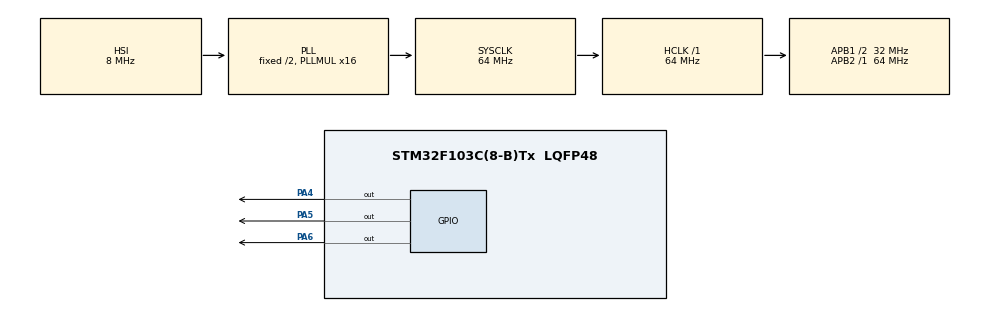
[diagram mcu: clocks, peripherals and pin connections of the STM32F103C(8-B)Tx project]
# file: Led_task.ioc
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Mcu.Family=STM32F1
Mcu.Name=STM32F103C(8-B)Tx
Mcu.Package=LQFP48
NVIC.PriorityGroup=NVIC_PRIORITYGROUP_4
NVIC.TIM4_IRQn=true\:15\:0\:false\:false\:true\:false\:true\:true
NVIC.TimeBase=TIM4_IRQn
NVIC.TimeBaseIP=TIM4
PA13.Mode=Serial_Wire
PA13.Signal=SYS_JTMS-SWDIO
PA14.Mode=Serial_Wire
PA14.Signal=SYS_JTCK-SWCLK
PA4.Signal=GPIO_Output
PA5.Signal=GPIO_Output
PA6.Signal=GPIO_Output
ProjectManager.HeapSize=0x200
ProjectManager.StackSize=0x400
ProjectManager.TargetToolchain=STM32CubeIDE
RCC.AHBFreq_Value=64000000
RCC.APB1CLKDivider=RCC_HCLK_DIV2
RCC.APB1Freq_Value=32000000
RCC.APB1TimFreq_Value=64000000
RCC.APB2Freq_Value=64000000
RCC.APB2TimFreq_Value=64000000
RCC.HCLKFreq_Value=64000000
RCC.PLLMUL=RCC_PLL_MUL16
RCC.SYSCLKFreq_VALUE=64000000
RCC.SYSCLKSource=RCC_SYSCLKSOURCE_PLLCLK
RCC.USBFreq_Value=64000000
VP_SYS_VS_tim4.Mode=TIM4
board=custom

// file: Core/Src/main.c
/* USER CODE BEGIN Header */
/**
  ******************************************************************************
  * @file           : main.c
  * @brief          : Main program body
  ******************************************************************************
  * @attention
  *
  * Copyright (c) 2023 STMicroelectronics.
  * All rights reserved.
  *
  * This software is licensed under terms that can be found in the LICENSE file
  * in the root directory of this software component.
  * If no LICENSE file comes with this software, it is provided AS-IS.
  *
  ******************************************************************************
  */
/* USER CODE END Header */
#include "main.h"

/* USER CODE BEGIN Includes */
#include "FreeRTOS.h"
#include "task.h"
/* USER CODE END Includes */

/* USER CODE BEGIN PV */
#define DWT_CTRL    (*(volatile uint32_t*)0xE0001000)
/* USER CODE END PV */

void SystemClock_Config(void);
static void MX_GPIO_Init(void);
/* USER CODE BEGIN PFP */
static void led_green_handler(void* parameters);
static void led_orange_handler(void* parameters);
static void led_red_handler(void* parameters);

/* USER CODE END PFP */

int main(void)
{
  /* USER CODE BEGIN 1 */
	TaskHandle_t task1_handle;
	TaskHandle_t task2_handle;
	TaskHandle_t task3_handle;
	BaseType_t status;
  /* USER CODE END 1 */

  /* MCU Configuration--------------------------------------------------------*/

  /* Reset of all peripherals, Initializes the Flash interface and the Systick. */
  HAL_Init();

  /* Configure the system clock */
  SystemClock_Config();

  /* Initialize all configured peripherals */
  MX_GPIO_Init();
  /* USER CODE BEGIN 2 */

  //CYCLCNT enable
  DWT_CTRL |= ( 1 << 0);

  SEGGER_SYSVIEW_Conf();
  SEGGER_SYSVIEW_Start();

  status = xTaskCreate(led_green_handler, "LED_green_task", 200, NULL, 2, &task1_handle);

  configASSERT(status == pdPASS);

  status = xTaskCreate(led_red_handler, "LED_red_task", 200,NULL, 2, &task2_handle);

  configASSERT(status == pdPASS);

  status = xTaskCreate(led_orange_handler, "LED_orange_task", 200, NULL, 2, &task3_handle);

  configASSERT(status == pdPASS);

  //start the freeRTOS scheduler
  vTaskStartScheduler();

  /* USER CODE END 2 */

  /* Infinite loop */
  while (1)
  {

  }
}

void SystemClock_Config(void)
{
  RCC_OscInitTypeDef RCC_OscInitStruct = {0};
  RCC_ClkInitTypeDef RCC_ClkInitStruct = {0};

  /** Initializes the RCC Oscillators according to the specified parameters
  * in the RCC_OscInitTypeDef structure.
  */
  RCC_OscInitStruct.OscillatorType = RCC_OSCILLATORTYPE_HSI;
  RCC_OscInitStruct.HSIState = RCC_HSI_ON;
  RCC_OscInitStruct.HSICalibrationValue = RCC_HSICALIBRATION_DEFAULT;
  RCC_OscInitStruct.PLL.PLLState = RCC_PLL_ON;
  RCC_OscInitStruct.PLL.PLLSource = RCC_PLLSOURCE_HSI_DIV2;
  RCC_OscInitStruct.PLL.PLLMUL = RCC_PLL_MUL16;
  if (HAL_RCC_OscConfig(&RCC_OscInitStruct) != HAL_OK)
  {
    Error_Handler();
  }

  /** Initializes the CPU, AHB and APB buses clocks
  */
  RCC_ClkInitStruct.ClockType = RCC_CLOCKTYPE_HCLK|RCC_CLOCKTYPE_SYSCLK
                              |RCC_CLOCKTYPE_PCLK1|RCC_CLOCKTYPE_PCLK2;
  RCC_ClkInitStruct.SYSCLKSource = RCC_SYSCLKSOURCE_PLLCLK;
  RCC_ClkInitStruct.AHBCLKDivider = RCC_SYSCLK_DIV1;
  RCC_ClkInitStruct.APB1CLKDivider = RCC_HCLK_DIV2;
  RCC_ClkInitStruct.APB2CLKDivider = RCC_HCLK_DIV1;

  if (HAL_RCC_ClockConfig(&RCC_ClkInitStruct, FLASH_LATENCY_2) != HAL_OK)
  {
    Error_Handler();
  }
}

static void MX_GPIO_Init(void)
{
  GPIO_InitTypeDef GPIO_InitStruct = {0};

  /* GPIO Ports Clock Enable */
  __HAL_RCC_GPIOA_CLK_ENABLE();

  /*Configure GPIO pin Output Level */
  HAL_GPIO_WritePin(GPIOA, GPIO_PIN_4|GPIO_PIN_5|GPIO_PIN_6, GPIO_PIN_RESET);

  /*Configure GPIO pins : PA4 PA5 PA6 */
  GPIO_InitStruct.Pin = GPIO_PIN_4|GPIO_PIN_5|GPIO_PIN_6;
  GPIO_InitStruct.Mode = GPIO_MODE_OUTPUT_PP;
  GPIO_InitStruct.Pull = GPIO_NOPULL;
  GPIO_InitStruct.Speed = GPIO_SPEED_FREQ_LOW;
  HAL_GPIO_Init(GPIOA, &GPIO_InitStruct);

}

/* USER CODE BEGIN 4 */
static void led_green_handler(void* parameters)
{

	while(1)
	{
		HAL_GPIO_TogglePin(GPIOA, GPIO_PIN_4);
//		HAL_Delay(1000);
		vTaskDelay(1000);
	}

}

static void led_orange_handler(void* parameters)
{
	while(1)
	{
		HAL_GPIO_TogglePin(GPIOA, GPIO_PIN_5);
//		HAL_Delay(800);
		vTaskDelay(800);
	}

}

static void led_red_handler(void* parameters)
{
	while(1)
	{
		HAL_GPIO_TogglePin(GPIOA, GPIO_PIN_6);
//		HAL_Delay(400);
		vTaskDelay(400);
	}

}
/* USER CODE END 4 */

void HAL_TIM_PeriodElapsedCallback(TIM_HandleTypeDef *htim)
{
  if (htim->Instance == TIM4) {
    HAL_IncTick();
  }
}

void Error_Handler(void)
{
  __disable_irq();
  while (1)
  {
  }
}
